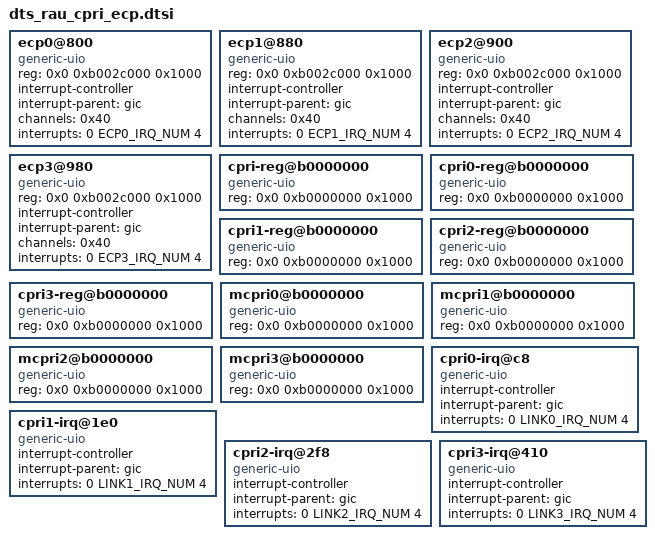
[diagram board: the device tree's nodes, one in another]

	ecp0@800 {
		compatible = "generic-uio";
		reg = < 0x0 0xb002c000 0x1000 >;
		interrupt-controller;
		interrupt-parent = <&gic>;
		channels = < 0x40 >;
		interrupts = < 0 ECP0_IRQ_NUM 4 >;
	};

	ecp1@880 {
		compatible = "generic-uio";
		reg = < 0x0 0xb002c000 0x1000 >;
		interrupt-controller;
		interrupt-parent = <&gic>;
		channels = < 0x40 >;
		interrupts = < 0 ECP1_IRQ_NUM 4 >;
	};

	ecp2@900 {
		compatible = "generic-uio";
		reg = < 0x0 0xb002c000 0x1000 >;
		interrupt-controller;
		interrupt-parent = <&gic>;
		channels = < 0x40 >;
		interrupts = < 0 ECP2_IRQ_NUM 4 >;
	};

	ecp3@980 {
		compatible = "generic-uio";
		reg = < 0x0 0xb002c000 0x1000 >;
		interrupt-controller;
		interrupt-parent = <&gic>;
		channels = < 0x40 >;
		interrupts = < 0 ECP3_IRQ_NUM 4 >;
	};



		cpri-reg@b0000000 {
			compatible = "generic-uio";
			reg = < 0x0 0xb0000000 0x1000 >;
		};

		cpri0-reg@b0000000 {
			compatible = "generic-uio";
			reg = < 0x0 0xb0000000 0x1000 >;
		};

		cpri1-reg@b0000000 {
			compatible = "generic-uio";
			reg = < 0x0 0xb0000000 0x1000 >;
		};

		cpri2-reg@b0000000 {
			compatible = "generic-uio";
			reg = < 0x0 0xb0000000 0x1000 >;
		};

		cpri3-reg@b0000000 {
			compatible = "generic-uio";
			reg = < 0x0 0xb0000000 0x1000 >;
		};

		mcpri0@b0000000 {
			compatible = "generic-uio";
			reg = < 0x0 0xb0000000 0x1000 >;
		};

		mcpri1@b0000000 {
			compatible = "generic-uio";
			reg = < 0x0 0xb0000000 0x1000 >;
		};

		mcpri2@b0000000 {
			compatible = "generic-uio";
			reg = < 0x0 0xb0000000 0x1000 >;
		};

		mcpri3@b0000000 {
			compatible = "generic-uio";
			reg = < 0x0 0xb0000000 0x1000 >;
		};

		cpri0-irq@c8 {
			compatible = "generic-uio";
			interrupt-controller;
			interrupt-parent = <&gic>;
			interrupts = < 0 LINK0_IRQ_NUM 4 >;
		};

		cpri1-irq@1e0 {
			compatible = "generic-uio";
			interrupt-controller;
			interrupt-parent = <&gic>;
			interrupts = < 0 LINK1_IRQ_NUM 4 >;
		};

		cpri2-irq@2f8 {
			compatible = "generic-uio";
			interrupt-controller;
			interrupt-parent = <&gic>;
			interrupts = < 0 LINK2_IRQ_NUM 4 >;
		};

		cpri3-irq@410 {
			compatible = "generic-uio";
			interrupt-controller;
			interrupt-parent = <&gic>;
			interrupts = < 0 LINK3_IRQ_NUM 4 >;
		};



